# PIC32CK2051SG00144 register map
Vendor: Microchip Technology; Series: PIC32CKSG00; File version: 0
CPU: CM33 r0p0, little endian, MPU, FPU, DSP, 3 interrupt priority bits, 158 interrupts, 23 SAU regions
Registers are 32-bit, read-write, reset 0x0 unless marked. A register's access mark holds for its fields unless they carry their own. Offsets are from the block's base; [hi:lo] are bit positions; 'fields as' and 'values as' point back to an identical list.

## PAC — Peripheral Access Controller
Base 0x4401C000
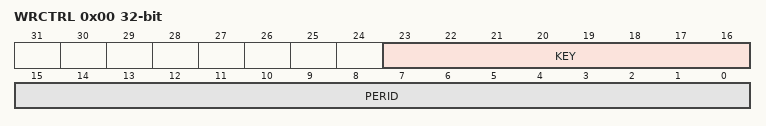
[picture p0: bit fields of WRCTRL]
0x00 WRCTRL — Write control
  [23:16] KEY — Peripheral access control key
    0=OFF (No action); 1=CLR (Clear protection); 2=SET (Set protection); 3=SETLCK (Set and lock protection)
  [15:0] PERID — Peripheral identifier
0x04 EVCTRL 8-bit — Event control
  [0] ERREO — Peripheral acess error event output
0x08 INTENCLR 8-bit write-1-clears — Interrupt enable clear
  [0] ERR — Peripheral access error interrupt disable
0x09 INTENSET 8-bit write-1-sets — Interrupt enable set
  [0] ERR — Peripheral access error interrupt enable
0x10 INTFLAGAHB write-1-clears — Bridge interrupt flag status
0x14 INTFLAGA write-1-clears — Peripheral interrupt flag status - Bridge A
0x18 INTFLAGB write-1-clears — Peripheral interrupt flag status - Bridge B
0x1C INTFLAGC write-1-clears — Peripheral interrupt flag status - Bridge C
0x20 INTFLAGD write-1-clears — Peripheral interrupt flag status - Bridge D
0x34 STATUSA ro reset 0xF0000 — Peripheral write protection status - Bridge A
0x38 STATUSB ro — Peripheral write protection status - Bridge B
0x3C STATUSC ro — Peripheral write protection status - Bridge C
0x40 STATUSD ro — Peripheral write protection status - Bridge D
0x54 NONSECA ro — Peripheral Non-Secure Status - Bridge A
0x58 NONSECB ro — Peripheral Non-Secure Status - Bridge B
0x5C NONSECC ro — Peripheral Non-Secure Status - Bridge C
0x60 NONSECD ro — Peripheral Non-Secure Status - Bridge D
0x74 SECLOCKA ro — Peripheral Security Lock Status - Bridge A
0x78 SECLOCKB ro — Peripheral Security Lock Status - Bridge B
0x7C SECLOCKC ro — Peripheral Security Lock Status - Bridge C
0x80 SECLOCKD ro — Peripheral Security Lock Status - Bridge D

## PCC — Parallel Capture Controller
Base 0x45018000
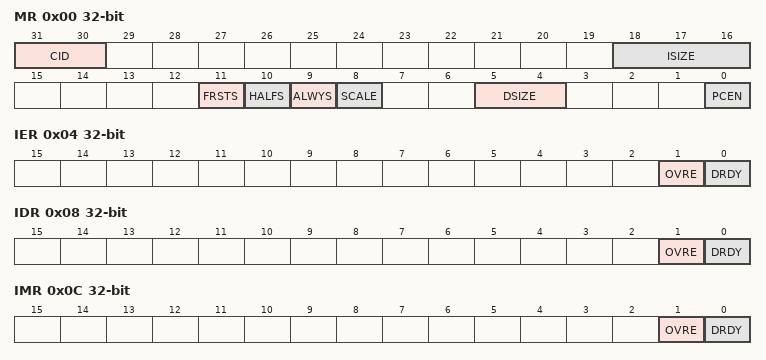
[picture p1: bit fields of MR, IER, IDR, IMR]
0x00 MR — Mode Register
  [31:30] CID — Clear If Disabled
  [18:16] ISIZE — Input Data Size
  [11] FRSTS — First sample
  [10] HALFS — Half Sampling
  [9] ALWYS — Always Sampling
  [8] SCALE — Scale data
  [5:4] DSIZE — Data size
  [0] PCEN — Parallel Capture Enable
0x04 IER wo — Interrupt Enable Register
  [1] OVRE — Overrun Error Interrupt Enable
  [0] DRDY — Data Ready Interrupt Enable
0x08 IDR wo — Interrupt Disable Register
  [1] OVRE — Overrun Error Interrupt Disable
  [0] DRDY — Data Ready Interrupt Disable
0x0C IMR ro — Interrupt Mask Register
  [1] OVRE — Overrun Error Interrupt Mask
  [0] DRDY — Data Ready Interrupt Mask
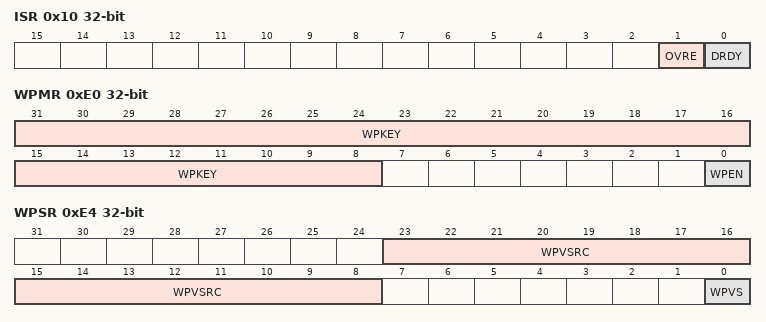
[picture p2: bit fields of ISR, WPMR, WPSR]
0x10 ISR ro — Interrupt Status Register
  [1] OVRE — Overrun Error Interrupt Status
  [0] DRDY — Data Ready Interrupt Status
0x14 RHR ro — Reception Holding Register
  [31:0] RDATA — Reception Data
0xE0 WPMR — Write Protection Mode Register
  [31:8] WPKEY — Write Protection Key
  [0] WPEN — Write Protection Enable
0xE4 WPSR ro — Write Protection Status Register
  [23:8] WPVSRC — Write Protection Violation Status
  [0] WPVS — Write Protection Violation Source

## PM — Power Manager
Base 0x44006000
0x00 CTRLA 8-bit — Control A
  [2] IORET — I/O Retention
    0=NOIORET (When the device exits the HIBERNATE or BACKUP mode, the I/O line configuration are released.); 1=IORET (When the device exits the HIBERNATE or BACKUP mode, the I/O line configuration are stretched.)
0x01 SLEEPCFG 8-bit reset 0x2 — Sleep Configuration
  [2:0] SLEEPMODE
    2=IDLE (CPU, AHB and APB clocks are OFF); 4=STANDBY (All Clocks are OFF); 5=HIBERNATE (Backup domain is ON as well as some PDRAMs); 6=BACKUP (Only Backup domain is powered ON); 7=OFF (All power domains are powered OFF)
0x04 INTENCLR 8-bit write-1-clears — Interrupt Enable Clear
  [0] SLEEPRDY — Backup Sleep Mode Entry Ready Enable
0x05 INTENSET 8-bit write-1-sets — Interrupt Enable Set
  [0] SLEEPRDY — Backup Sleep Mode Entry Ready Enable
0x06 INTFLAG 8-bit reset 0x1 write-1-clears — Interrupt Flag Status and Clear
  [0] SLEEPRDY — Backup Sleep Mode Entry Ready
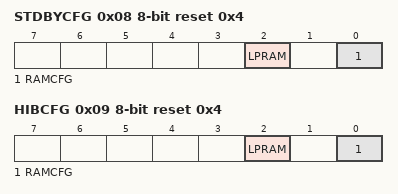
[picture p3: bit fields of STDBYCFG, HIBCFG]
0x08 STDBYCFG 8-bit reset 0x4 — Standby Configuration
  [2] LPRAM — Low Power RAM Enable
  [0] RAMCFG — Ram Configuration
    0=RET (All the RAMs are retained); 1=OFF (Only the first 32K bytes are retained)
0x09 HIBCFG 8-bit reset 0x4 — Hibernate Configuration
  fields as STDBYCFG
